# YTM32B1ME0 register map
Vendor: YTMicro; File version: 1.2
CPU: CM33 r0p4, little endian, MPU, FPU, 2 interrupt priority bits
Registers are 32-bit, read-write, reset 0x0 unless marked. A register's access mark holds for its fields unless they carry their own. Offsets are from the block's base; [hi:lo] are bit positions; {n}, {i} and the like mark numbered series.

## EFM — Embedded FLASH Module
Base 0x40010000; register names take the prefix EFM_
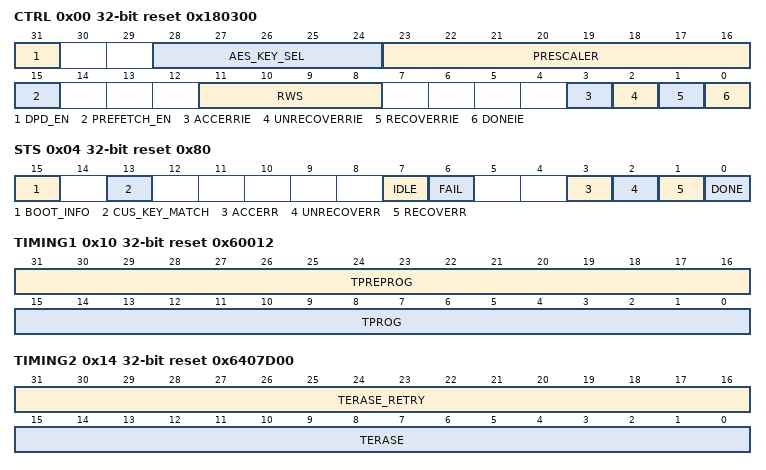
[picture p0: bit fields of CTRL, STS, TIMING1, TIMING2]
0x00 CTRL reset 0x180300
  [31] DPD_EN — This DPD_EN bit determines whether the flash will enter deep power-down mode when MCU is entering Deepsleep mode.
    0=Flash will keep active when MCU enters Deepsleep mode; 1=Flash will enter deep power-down mode when MCU enters Deepsleep mode
  [28:24] AES_KEY_SEL — These AES_KEY_SEL bits are used for selecting one of several AES keys stored in the customer NVR region.
  [23:16] PRESCALER — These PRESCALER bits are used for EFM operation timing control. ewline These bits need to be programmed to half of core frequency. ewline Please use the following equation to calculate the PRESCALER value: ewline PRESCALER = core frequency / 2. ewline Please note that once the core frequency is changed, this field needs to be set to the appropriate value.
  [15] PREFETCH_EN — This PREFETCH_EN bit is used for enabling prefetch read functionality.
  [11:8] RWS
  [3] ACCERRIE — This ACCERRIE bit determines whether the interrupt will be generated if ACCERR flag is asserted.
    0=Disable generating interrupt if ACCERR flag is asserted; 1=Enable generating interrupt if ACCERR flag is asserted
  [2] UNRECOVERRIE — This UNRECOVERRIE bit determines whether the interrupt will be generated if UNRECOVERR flag is asserted.
    0=Disable generating interrupt if UNRECOVERR flag is asserted; 1=Enable generating interrupt if UNRECOVERR flag is asserted
  [1] RECOVERRIE — This RECOVERRIE bit determines whether the interrupt will be generated if RECOVERR flag is asserted.
    0=Disable generating interrupt if RECOVERR flag is asserted; 1=Enable generating interrupt if RECOVERR flag is asserted
  [0] DONEIE — This DONEIE bit determines whether the interrupt will be generated if DONE flag is asserted.
    0=Disable generating interrupt if DONE flag is asserted; 1=Enable generating interrupt if DONE flag is asserted
0x04 STS reset 0x80
  [15] BOOT_INFO ro — This BOOT_INFO bit indicates flash loads codes from Block 0 or Block 1.
    0=Flash is loading codes from Block 0; 1=Flash is loading codes from Block 1
  [13] CUS_KEY_MATCH ro — This CUS_KEY_MATCH bit indicates whether Customer Key is matched.
    0=Customer Key is not matched; 1=Customer Key is matched
  [7] IDLE ro — This IDLE bit indicates whether flash is executing a command.
    0=Flash is currently executing a command; 1=No command is currently being executed
  [6] FAIL — This FAIL bit indicates whether the current command is failed. ewline Command fail includes below scenarios: ewline 1.program verify is failed. ewline 2.erase verify is failed.
    0=Current command is succeeds; 1=Current command is fails
  [3] ACCERR — This ACCERR bit indicates whether there is an access error is detected. ewline Accerr error includes below scenarios: ewline 1.Access flash when IDLE is de-asserted. ewline 2.Launch a new command when IDLE is de-asserted. ewline 3.Lack of address or data information before launching the program or erase command.
    0=Access error is not detected; 1=Access error is detected
  [2] UNRECOVERR — This UNRECOVERR bit indicates whether more than 2-bit ECC error is detected.
    0=No unrecovery ECC error; 1=2-bit ECC error or multi-bit ECC error
  [1] RECOVERR — This RECOVERR bit indicates whether there is a recovery ecc error is detected.
    0=Recovery ecc error is not detected; 1=1-bit ECC error is detected
  [0] DONE — This DONE bit indicates whether the current command is completed.
    0=Current command is in progress; 1=Current command is completed
0x08 CMD
  [7:0] CMD — These CMD bits determine which commands are available.
    2=Program 64bits (0x02); 3=Program 64bits and then verify (0x03); 16=Erase sector (0x10); 17=Erase sector and then verify (0x11); 18=Erase block (only main array) (0x12); 19=Erase block and then verify (only main array) (0x13); 32=Load AES Key (0x20); 48=Boot Swap (0x30); 64=Program NVR (0x40); 65=Erase NVR (0x41); 66=Read NVR (0x42)
0x10 TIMING1 reset 0x60012
  [31:16] TPREPROG — These TPREPROG bits indicate the pre-program time, and the time unit is 0.5us. ewline Please use the following equation to calculate TPREPROG value: ewline TPREPROG = (2.5 to 3.5) * 2
  [15:0] TPROG — These TPROG bits indicate the program time, and the time unit is 0.5us. ewline Please use the following equation to calculate TPROG value: ewline TPROG = (8 to 10) * 2
0x14 TIMING2 reset 0x6407D00
  [31:16] TERASE_RETRY — These TERASE_RETRY bits indicate the erase-retry time, and the time unit is 0.5us. ewline Please use the following equation to calculate TERASE_RETRY value: ewline TERASE = (0.8 to 1) * 1000 * 2 ewline Please note that both erase-retry is only for main array sector erase.
  [15:0] TERASE — These TERASE bits indicate the erase time, and the time unit is 0.5us. ewline Please use the following equation to calculate TERASE value: ewline TERASE = (16 to 20) * 1000 * 2 ewline Please note that both sector erase (not includes erase-retry) and chip erase got the same erase time.
0x18 NVR_ADDR
  [31:0] NVR_ADDR — NVR Access Address
0x1C NVR_DATA0
  [31:0] EFM_NVR_DATA — NVR Access data
0x20 NVR_DATA1
  [31:0] EFM_NVR_DATA — NVR Access data
{0x24+4i} ADDR_PROT{i} reset 0xFFFFFFFF (i=0..2)
  [31:0] ADDR_PROT — Each bit protects (block size/32) address area. If the bit is set to 0, corresponding area is under protection.
0x30 ERR_ADDR
  [31:0] ECC_ERR_ADDR — These bits indicate current main array address of Unrecovery Ecc Error
0x200 CMD_UNLOCK
  [31:0] CMD_UNLOCK_KEY wo — Please write 0xfd9573f5 before launching any command
0x204 CUS_KEY
  [23:0] CUS_KEY wo — Please write Customer Key(0x4dff32) before any protected NVR operation
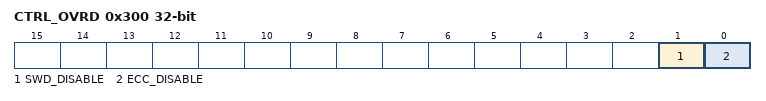
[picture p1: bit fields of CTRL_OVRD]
0x300 CTRL_OVRD
  [1] SWD_DISABLE — This bit determines whether the Software Debugger is override disabled.
    0=Software Debugger is not override disabled; 1=Software Debugger is override disabled
  [0] ECC_DISABLE — This bit determines whether the ECC is override disabled
    0=ECC is not override disabled; 1=ECC is override disabled
0x308 CFG_KEY
  [23:0] CFG_KEY wo — Please write Config Key before any protected NVR operation

## Notices in the file
YTMicro Microcontroller all rights reserved.
